# STM32F303 register map
File version: 1.7
Registers are 32-bit, read-write, reset 0x0 unless marked. A register's access mark holds for its fields unless they carry their own. Offsets are from the block's base; [hi:lo] are bit positions; {n}, {i} and the like mark numbered series; 'fields as' and 'values as' point back to an identical list.

## FMC — Flexible memory controller
Base 0xA0000400
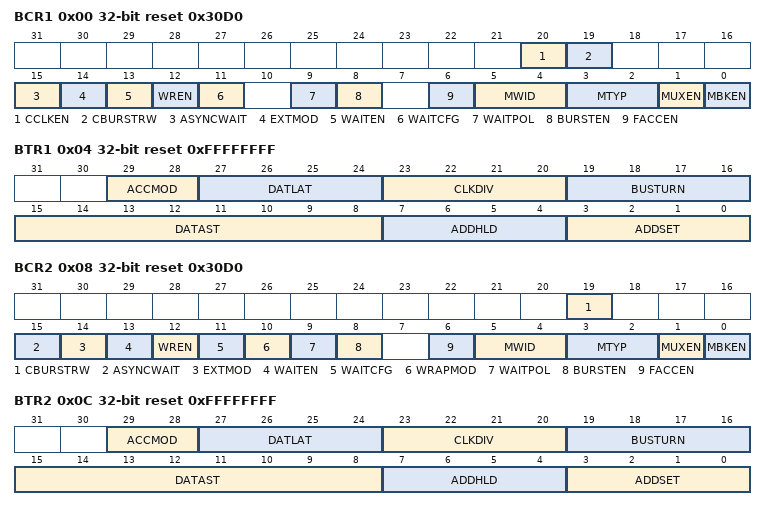
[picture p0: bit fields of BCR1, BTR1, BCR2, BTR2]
0x00 BCR1 reset 0x30D0 — SRAM/NOR-Flash chip-select control register 1
  [20] CCLKEN, [19] CBURSTRW, [15] ASYNCWAIT, [14] EXTMOD, [13] WAITEN, [12] WREN, [11] WAITCFG, [9] WAITPOL, [8] BURSTEN, [6] FACCEN, [5:4] MWID, [3:2] MTYP, [1] MUXEN, [0] MBKEN
0x04 BTR1 reset 0xFFFFFFFF — SRAM/NOR-Flash chip-select timing register 1
  [29:28] ACCMOD, [27:24] DATLAT, [23:20] CLKDIV, [19:16] BUSTURN, [15:8] DATAST, [7:4] ADDHLD, [3:0] ADDSET
0x08 BCR2 reset 0x30D0 — SRAM/NOR-Flash chip-select control register 2
  [19] CBURSTRW, [15] ASYNCWAIT, [14] EXTMOD, [13] WAITEN, [12] WREN, [11] WAITCFG, [10] WRAPMOD, [9] WAITPOL, [8] BURSTEN, [6] FACCEN, [5:4] MWID, [3:2] MTYP, [1] MUXEN, [0] MBKEN
0x0C BTR2 reset 0xFFFFFFFF — SRAM/NOR-Flash chip-select timing register 2
  fields as BTR1
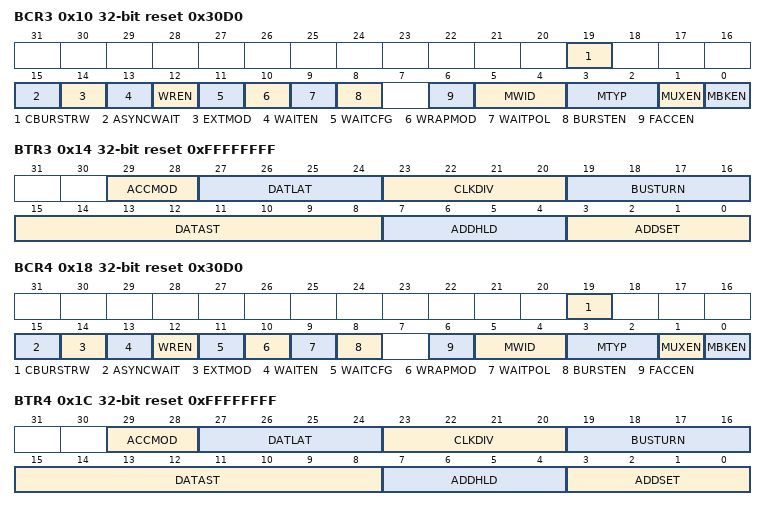
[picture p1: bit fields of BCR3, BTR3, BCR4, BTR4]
0x10 BCR3 reset 0x30D0 — SRAM/NOR-Flash chip-select control register 3
  fields as BCR2
0x14 BTR3 reset 0xFFFFFFFF — SRAM/NOR-Flash chip-select timing register 3
  fields as BTR1
0x18 BCR4 reset 0x30D0 — SRAM/NOR-Flash chip-select control register 4
  fields as BCR2
0x1C BTR4 reset 0xFFFFFFFF — SRAM/NOR-Flash chip-select timing register 4
  fields as BTR1
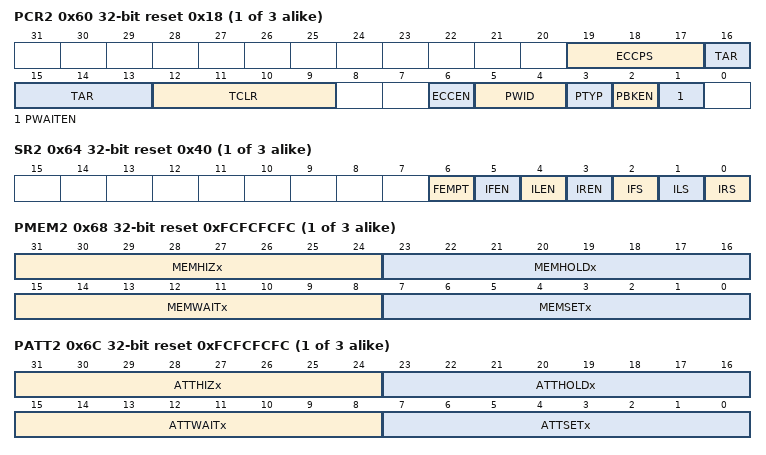
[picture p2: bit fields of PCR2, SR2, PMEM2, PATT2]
{0x20+0x20*i} PCR{i} reset 0x18 (i=2..4) — PC Card/NAND Flash control register {i}
  [19:17] ECCPS, [16:13] TAR, [12:9] TCLR, [6] ECCEN, [5:4] PWID, [3] PTYP, [2] PBKEN, [1] PWAITEN
{0x24+0x20*i} SR{i} access per field reset 0x40 (i=2..4) — FIFO status and interrupt register {i}
  [6] FEMPT ro, [5] IFEN rw, [4] ILEN rw, [3] IREN rw, [2] IFS rw, [1] ILS rw, [0] IRS rw
{0x28+0x20*i} PMEM{i} reset 0xFCFCFCFC (i=2..4) — Common memory space timing register {i}
  [31:24] MEMHIZx, [23:16] MEMHOLDx, [15:8] MEMWAITx, [7:0] MEMSETx
{0x2C+0x20*i} PATT{i} reset 0xFCFCFCFC (i=2..4) — Attribute memory space timing register {i}
  [31:24] ATTHIZx, [23:16] ATTHOLDx, [15:8] ATTWAITx, [7:0] ATTSETx
0x74 ECCR2 ro — ECC result register 2
  [31:0] ECCx
0x94 ECCR3 ro — ECC result register 3
  [31:0] ECCx
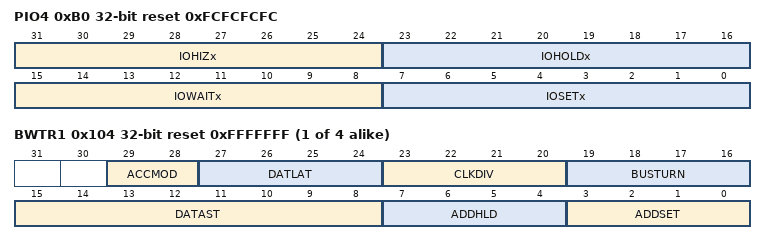
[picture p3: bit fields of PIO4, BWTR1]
0xB0 PIO4 reset 0xFCFCFCFC — I/O space timing register 4
  [31:24] IOHIZx, [23:16] IOHOLDx, [15:8] IOWAITx, [7:0] IOSETx
{0xFC+8i} BWTR{i} reset 0xFFFFFFF (i=1..4) — SRAM/NOR-Flash write timing registers {i}
  [29:28] ACCMOD
  [27:24] DATLAT
  [23:20] CLKDIV
  [19:16] BUSTURN — Bus turnaround phase duration
  [15:8] DATAST
  [7:4] ADDHLD
  [3:0] ADDSET

## NVIC — Nested Vectored Interrupt Controller
Base 0xE000E100
0x00 ISER0 — Interrupt Set-Enable Register
  [31:0] SETENA
0x04 ISER1 — Interrupt Set-Enable Register
  [31:0] SETENA
0x80 ICER0 — Interrupt Clear-Enable Register
  [31:0] CLRENA
0x84 ICER1 — Interrupt Clear-Enable Register
  [31:0] CLRENA
0x100 ISPR0 — Interrupt Set-Pending Register
  [31:0] SETPEND
0x104 ISPR1 — Interrupt Set-Pending Register
  [31:0] SETPEND
0x180 ICPR0 — Interrupt Clear-Pending Register
  [31:0] CLRPEND
0x184 ICPR1 — Interrupt Clear-Pending Register
  [31:0] CLRPEND
0x200 IABR0 ro — Interrupt Active Bit Register
  [31:0] ACTIVE
0x204 IABR1 ro — Interrupt Active Bit Register
  [31:0] ACTIVE
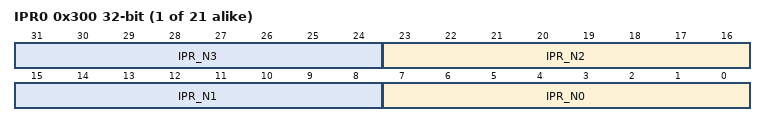
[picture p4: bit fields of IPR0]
{0x300+4i} IPR{i} (i=0..20) — Interrupt Priority Register
  [8n+7:8n] IPR_N{n} (n=0..3)
0x354 IPR21 — Interrupt Priority Register
0x358 IPR22 — Interrupt Priority Register

## FPU — Floting point unit
Base 0xE000EF34
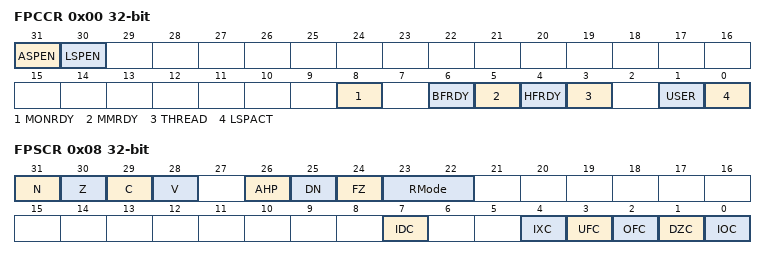
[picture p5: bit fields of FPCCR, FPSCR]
0x00 FPCCR — Floating-point context control register
  [31] ASPEN, [30] LSPEN, [8] MONRDY, [6] BFRDY, [5] MMRDY, [4] HFRDY, [3] THREAD, [1] USER, [0] LSPACT
0x04 FPCAR — Floating-point context address register
  [31:3] ADDRESS — Location of unpopulated floating-point
0x08 FPSCR — Floating-point status control register
  [31] N — Negative condition code flag
  [30] Z — Zero condition code flag
  [29] C — Carry condition code flag
  [28] V — Overflow condition code flag
  [26] AHP — Alternative half-precision control bit
  [25] DN — Default NaN mode control bit
  [24] FZ — Flush-to-zero mode control bit:
  [23:22] RMode — Rounding Mode control field
  [7] IDC — Input denormal cumulative exception bit.
  [4] IXC — Inexact cumulative exception bit
  [3] UFC — Underflow cumulative exception bit
  [2] OFC — Overflow cumulative exception bit
  [1] DZC — Division by zero cumulative exception bit.
  [0] IOC — Invalid operation cumulative exception bit

## MPU — Memory protection unit
Base 0xE000ED90
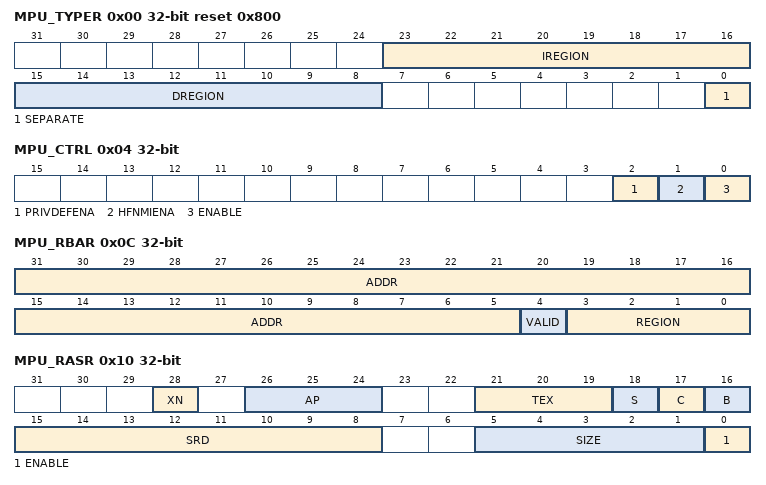
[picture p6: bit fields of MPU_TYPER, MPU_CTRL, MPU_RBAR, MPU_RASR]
0x00 MPU_TYPER ro reset 0x800 — MPU type register
  [23:16] IREGION — Number of MPU instruction regions
  [15:8] DREGION — Number of MPU data regions
  [0] SEPARATE — Separate flag
0x04 MPU_CTRL ro — MPU control register
  [2] PRIVDEFENA — Enable priviliged software access to default memory map
  [1] HFNMIENA — Enables the operation of MPU during hard fault
  [0] ENABLE — Enables the MPU
0x08 MPU_RNR — MPU region number register
  [7:0] REGION — MPU region
0x0C MPU_RBAR — MPU region base address register
  [31:5] ADDR — Region base address field
  [4] VALID — MPU region number valid
  [3:0] REGION — MPU region field
0x10 MPU_RASR — MPU region attribute and size register
  [28] XN — Instruction access disable bit
  [26:24] AP — Access permission
  [21:19] TEX — memory attribute
  [18] S — Shareable memory attribute
  [17] C — memory attribute
  [16] B — memory attribute
  [15:8] SRD — Subregion disable bits
  [5:1] SIZE — Size of the MPU protection region
  [0] ENABLE — Region enable bit.

## STK — SysTick timer
Base 0xE000E010
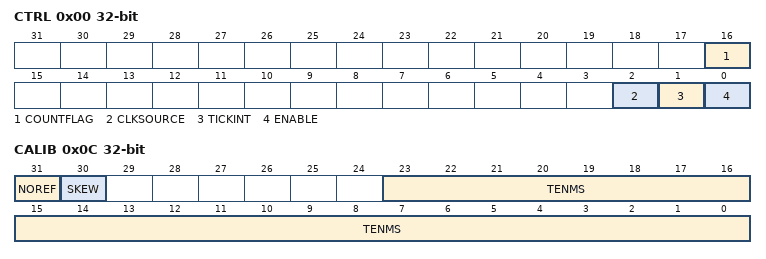
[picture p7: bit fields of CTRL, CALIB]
0x00 CTRL — SysTick control and status register
  [16] COUNTFLAG
  [2] CLKSOURCE — Clock source selection
  [1] TICKINT — SysTick exception request enable
  [0] ENABLE — Counter enable
0x04 LOAD — SysTick reload value register
  [23:0] RELOAD — RELOAD value
0x08 VAL — SysTick current value register
  [23:0] CURRENT — Current counter value
0x0C CALIB — SysTick calibration value register
  [31] NOREF — NOREF flag. Reads as zero
  [30] SKEW — SKEW flag: Indicates whether the TENMS value is exact
  [23:0] TENMS — Calibration value

## NVIC_STIR — Nested vectored interrupt controller
Base 0xE000EF00
0x00 STIR — Software trigger interrupt register
  [8:0] INTID — Software generated interrupt ID

## FPU_CPACR — Floating point unit CPACR
Base 0xE000ED88
0x00 CPACR — Coprocessor access control register
  [23:20] CP

## SCB_ACTRL — System control block ACTLR
Base 0xE000E008
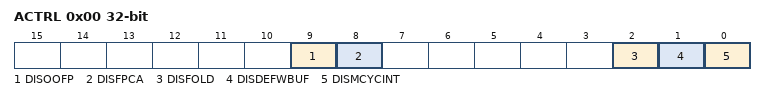
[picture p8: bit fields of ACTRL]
0x00 ACTRL — Auxiliary control register
  [9] DISOOFP, [8] DISFPCA, [2] DISFOLD, [1] DISDEFWBUF, [0] DISMCYCINT
